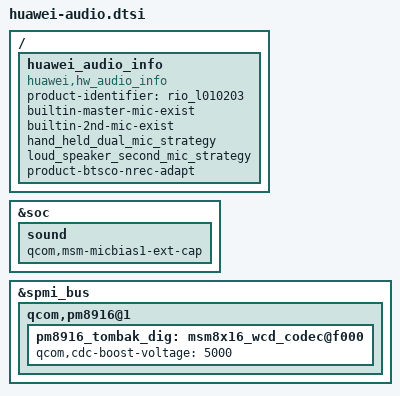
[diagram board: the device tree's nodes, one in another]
/* < DTS2015030601036 lixiuzhen 20150306 begin */
/* < DTS2015062500056 lugandong 20150625 begin */
/ {
    huawei_audio_info {
        compatible = "huawei,hw_audio_info";
        product-identifier = "rio_l010203";
        builtin-master-mic-exist;
        builtin-2nd-mic-exist;
        hand_held_dual_mic_strategy;
        status = "ok";
        loud_speaker_second_mic_strategy;
        product-btsco-nrec-adapt;
    };
};
&soc {
    sound {
        qcom,msm-micbias1-ext-cap;
    };
};
&spmi_bus {
        qcom,pm8916@1 {
                pm8916_tombak_dig: msm8x16_wcd_codec@f000{
                        qcom,cdc-boost-voltage = <5000>;
                };
        };
};
/* DTS2015062500056 lugandong 20150625 end > */
/* DTS2015030601036 lixiuzhen 20150306 end > */
